# SF32LB57x register map
File version: 1.0
CPU: CM33 r0p1, little endian, MPU, FPU, 3 interrupt priority bits
Registers are 32-bit, read-write, reset 0x0 unless marked. A register's access mark holds for its fields unless they carry their own. Offsets are from the block's base; [hi:lo] are bit positions; {n}, {i} and the like mark numbered series.

## PTM1
Base 0x500A1000
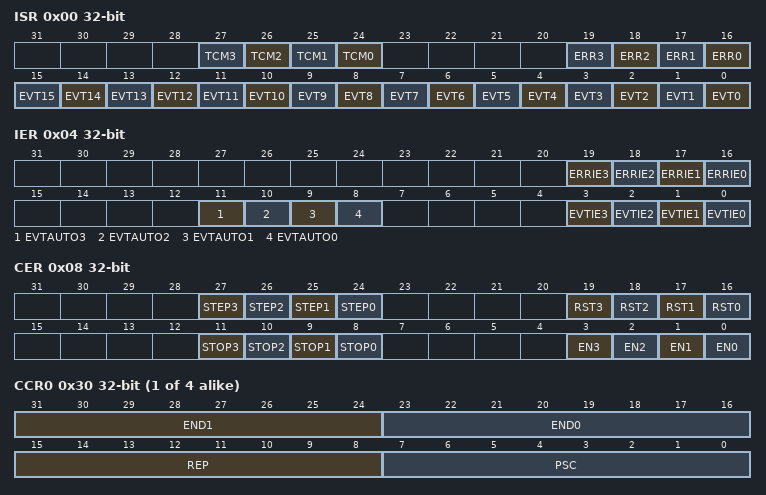
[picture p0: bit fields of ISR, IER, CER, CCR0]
0x00 ISR — interrupt status register
  [n+24] TCM{n} (n=0..3) — TCM collision flag of core {n}, will be cleared by CER_RST{n}
  [n+16] ERR{n} (n=0..3) — bus error or illegal instruction flag of core {n}, will be cleared by CER_RST{n}
  [n] EVT{n} (n=4..15) — event flag {n}, set by instruction. Write 1 clear. Write 0 no effect.
  [n] EVT{n} (n=0..3) — event flag {n}, set by instruction. Write 1 clear. Write 0 no effect. Set when core {n} execution done and IER_EVTAUTO{n} is 1.
0x04 IER — interrupt enable register
  [19] ERRIE3 — enable error interrupt of core 3
  [18] ERRIE2 — enable error interrupt of core 2
  [17] ERRIE1 — enable error interrupt of core 1
  [16] ERRIE0 — enable error interrupt of core 0, including bus error, illegal instruction and tcm collision
  [11] EVTAUTO3 — enable auto event 3
  [10] EVTAUTO2 — enable auto event 2
  [9] EVTAUTO1 — enable auto event 1
  [8] EVTAUTO0 — enable auto event 0 1: event 0 will assert automatically when core 0 execution done (repetition done). 0: no auto event 0
  [3] EVTIE3 — enable event 3 interrupt
  [2] EVTIE2 — enable event 2 interrupt
  [1] EVTIE1 — enable event 1 interrupt
  [0] EVTIE0 — enable event 0 interrupt 1: event 0 interrupt enabled 0: event 0 interrupt disabled
0x08 CER — Core Enable Register
  [27] STEP3 — core 3 single step
  [26] STEP2 — core 2 single step
  [25] STEP1 — core 1 single step
  [24] STEP0 — core 0 single step write 1 to step. Core will execute the next instruction, then stop automatically. write 0 has no effect
  [19] RST3 — reset core 3
  [18] RST2 — reset core 2
  [17] RST1 — reset core 1
  [16] RST0 — write 1 to reset core 0. Will reset all status and registers including X/Y/A/B/PC/FIFO. TCM code will not be affected. write 0 has no effect
  [11] STOP3 — stop core 3
  [10] STOP2 — stop core 2
  [9] STOP1 — stop core 1
  [8] STOP0 — write 1 to stop core 0 write 0 has no effect
  [3] EN3 — enable core 3
  [2] EN2 — enable core 2
  [1] EN1 — enable core 1
  [0] EN0 — write 1 to enable core 0 write 0 has no effect read 1 indicates core is working read 0 indicates core is not working
0x10 DOER — Data Output Enable Register
  [15:0] DOE — Read as output enable of PTM_CH. Bit n is for PTM_CH[n]. Should be modified by instruction or by setting DOESR/DOECR registers.
0x14 DOR — Data Output Register
  [15:0] DO — Read as output value of PTM_CH. Bit n is for PTM_CH[n]. Should be modified by instruction or by setting DOSR/DOCR registers.
0x18 DOESR — Data Output Enable Set Register
  [15:0] DOES — Write 1 to bit n: set output enable of PTM_CH[n] to 1. Write 0 to bit n: no effect.
0x1C DOECR — Data Output Enable Clear Register
  [15:0] DOEC — Write 1 to bit n: set output enable of PTM_CH[n] to 0. Write 0 to bit n: no effect.
0x20 DOSR — Data Output Set Register
  [15:0] DOS — Write 1 to bit n: set output value of PTM_CH[n] to 1. Write 0 to bit n: no effect.
0x24 DOCR — Data Output Clear Register
  [15:0] DOC — Write 1 to bit n: set output value of PTM_CH[n] to 0. Write 0 to bit n: no effect.
{0x30+0x30*i} CCR{i} (i=0..3) — Core {i} control register
  [31:24] END1 — Another TCM instruction index to end instruction sequence. After executes this instruction, current core will stop execution if REP=0, or restart from index 0 if REP!=0
  [23:16] END0 — TCM instruction index to end instruction sequence. After executes this instruction, current core will stop execution if REP=0, or restart from index 0 if REP!=0
  [15:8] REP — Repetition times for instruction sequence. 0: No repetition. Core will stop after executes TCM instruction of index END0 or END1. 1~254: Finite Repetition. Core will restart from index 0 after executes TCM instruction of index END0 or END1, and REP will be decreased by 1, until REP become 0. 255: Infinite Repetion. Core will restart from index 0 after executes TCM instruction of index END0 or END1, and REP will not be decreased.
  [7:0] PSC — Prescaler factor. Core will execute at a divided rate of hclk/(PSC+1). All instructions will be affected.
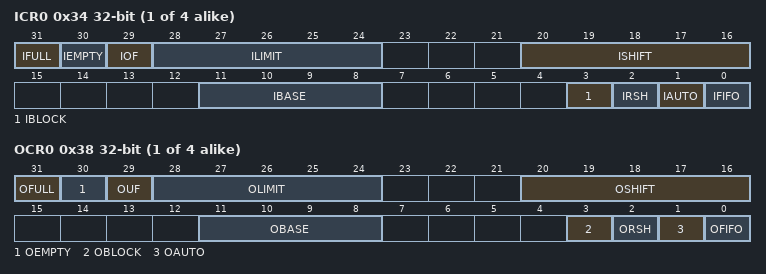
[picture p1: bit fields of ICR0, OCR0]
{0x34+0x30*i} ICR{i} (i=0..3) — Input control register for core {i}
  [31] IFULL — 1: IFIFO is full 0: IFIFO is not full
  [30] IEMPTY — 1: IFIFO is empty 0: IFIFO is not empty
  [29] IOF — 1: IFIFO overflow occurs, when new data is to be pushed into IFIFO but IFIFO is already full, thus the new data is discarded 0: IFIFO never overflow
  [28:24] ILIMIT — Input threshold for IFIFO auto push, valid when IAUTO=1. 0: Input threshold is 32 others: Input threshold is ILIMIT If accumulated input bit counter(named as Y_CNT) reaches or exceeds input threshold, input data stored in Y register will be pushed into IFIFO automatically, and accumulated input bit counter is cleared to 0.
  [20:16] ISHIFT — Shift bit count of Y register when Y is automatically pushed into IFIFO, valid when IAUTO=1. Data pushed into IFIFO is Y left shifted by ISHIFT if IRSH=0, or Y right shifted by ISHIFT if IRSH=1. Only valid for automatic IFIFO push of PTM_IO instruction. When pushing IFIFO by PTM_SET instruction, shift processing should be coded in the OP and IMM16 field of the instruction instead of ISHIFT.
  [11:8] IBASE — Input offset for this core. CORE_IN[n] = PTM_CH[(n+IBASE) round 16] For example, if IBASE=5, CORE_IN[0] = PTM_CH[5], CORE_IN[11] = PTM_CH[0], CORE_IN[15] = PTM_CH[4]
  [3] IBLOCK — 1: Core execution is blocked if a new data is to be pushed into IFIFO but IFIFO is already full. Related instruction are PTM_IO and PTM_SET. Core execution will continue if the data can be successfully pushed into IFIFO after IFIFO been fetched by CPU or DMA. 0: Core execution will not be blocked, so IFIFO may overflow. New data will be discarded.
  [2] IRSH — 1: for PTM_IO instruction, Y register will be right shifted, and CORE_IN signals will be placed from MSB of Y register. For example, if PTM_IO input 8-bit signal, Y will be right shifted by 8, and CORE_IN[0]->Y[31], CORE_IN[1]->Y[30] ...... CORE_IN[7]->Y[24]. When Y is automatically pushed into IFIFO, pushed data will be additionally right shifted by ISHIFT. This is useful when input sequence is LSB first but data need to be stored in lower bits of a word. 0: for PTM_IO instruction, Y register will be left shifted, and CORE_IN data will be placed from LSB of Y register. For example, if PTM_IO input 8-bit signal, Y will be left shifted by 8, and CORE_IN[0]->Y[0], CORE_IN[1]->Y[1] ...... CORE_IN[7]->Y[7]. When Y is automatically pushed into IFIFO, pushed data will be additionally left shifted by ISHIFT. This is useful when input sequence is MSB first but data need to be stored in higher bits of a word.
  [1] IAUTO — 1: If accumulated input bit counter reaches or exceeds input threshold, input data stored in Y register will be pushed into IFIFO automatically, and accumulated input bit counter is cleared to 0. 0: Y register will not be pushed into IFIFO automatically. PTM_SET instruction can push IFIFO instead.
  [0] IFIFO — 1: IFIFO enabled. IFIFO depth will be 4 if OFIFO also enabled, and be 8 if OFIFO disabled. 0: IFIFO disabled.
{0x38+0x30*i} OCR{i} (i=0..3) — Output control register for core {i}
  [31] OFULL — 1: OFIFO is full 0: OFIFO is not full
  [30] OEMPTY — 1: OFIFO is empty 0: OFIFO is not empty
  [29] OUF — 1: OFIFO underflow occurs, which means new data is to be poped from OFIFO but OFIFO is empty, thus the poped data is 0 0: OFIFO never underflow
  [28:24] OLIMIT — Output bit counter for OFIFO auto pop, valid when OAUTO=1. 0: Output bit counter is 32 others: Output bit counter is OLIMIT If left output bit counter(named as X_CNT) reaches 0, OFIFO will be poped to X register automatically, and left output bit counter is reset to OLIMIT.
  [20:16] OSHIFT — Shift bit count of OFIFO data when OFIFO is automatically poped into X register, valid when OAUTO=1. Data poped from OFIFO is left shifted by OSHIFT if ORSH=0, or right shifted by OSHIFT if ORSH=1, before storing into X register. Only valid for automatic OFIFO pop of PTM_IO instruction. When poping OFIFO by PTM_SET instruction, shift processing should be coded in the OP and IMM16 field of the instruction instead of OSHIFT.
  [11:8] OBASE — Output offset for this core. PTM_CH[(n+IBASE) round 16] = CORE_OUT[n] For example, if OBASE=5, PTM_CH[5] = CORE_OUT[0], PTM_CH[0] = CORE_OUT[11], PTM_CH[4] = CORE_OUT[15]
  [3] OBLOCK — 1: Core execution is blocked if a new data is to be poped from OFIFO but OFIFO is empty. Related instruction are PTM_IO and PTM_SET. Core execution will continue if data can be successfully poped from OFIFO after OFIFO been filled by CPU or DMA. 0: Core execution will not be blocked, so OFIFO may underflow. Poped data will be 0.
  [2] ORSH — 1: for PTM_IO instruction, CORE_OUT signals will be pushed from LSB of X register, and X register will be right shifted. For example, if PTM_IO output 8-bit signal, X[0] ->CORE_OUT[0], X[1] ->CORE_OUT[1] ...... X[7] ->CORE_OUT[7], and X will be right shifted by 8. When OFIFO is automatically poped, poped data will be right shifted by OSHIFT before set to X. This is useful when output sequence is LSB first but data need to be stored in higher bits of a word. 0: for PTM_IO instruction, CORE_OUT signals will be pushed from MSB of X register, and X register will be left shifted. For example, if PTM_IO output 8-bit signal, X[31] ->CORE_OUT[0], X[30] ->CORE_OUT[1] ...... X[24] ->CORE_OUT[7], and X will be left shifted by 8. When OFIFO is automatically poped, poped data will be left shifted by OSHIFT before set to X. This is useful when output sequence is MSB first but data need to be stored in lower bits of a word.
  [1] OAUTO — 1: If left output bit counter reaches 0, OFIFO will be poped to X register automatically, and left output bit counter is reset to OLIMIT. 0: OFIFO will not be poped to X register automatically. PTM_SET instruction can pop OFIFO instead.
  [0] OFIFO — 1: OFIFO enabled. OFIFO depth will be 4 if IFIFO also enabled, and be 8 if IFIFO disabled. 0: OFIFO disabled.
{0x3C+0x30*i} X{i} (i=0..3) — X register for core {i}
  [31:0] VAL — Instant value of X register. Bit 31 to 16 is XH register. Bit 15 to 0 is XL register.
{0x40+0x30*i} Y{i} (i=0..3) — Y register for core {i}
  [31:0] VAL — Instant value of Y register. Bit 31 to 16 is YH register. Bit 15 to 0 is YL register.
{0x44+0x30*i} A{i} (i=0..3) — A register for core {i}
  [15:0] VAL — Instant value of A register.
{0x48+0x30*i} B{i} (i=0..3) — B register for core {i}
  [15:0] VAL — Instant value of B register.
{0x4C+0x30*i} PC{i} (i=0..3) — PC register for core {i}
  [31:0] VAL — Instant value of PC(program counter).
{0x50+0x30*i} IFIFO{i} (i=0..3) — IFIFO entry for core {i}
  [31:0] DAT — Read this entry to pop IFIFO. Return 0 if IFIFO empty.
{0x54+0x30*i} OFIFO{i} (i=0..3) — OFIFO entry for core {i}
  [31:0] DAT — Write this entry to push OFIFO.
